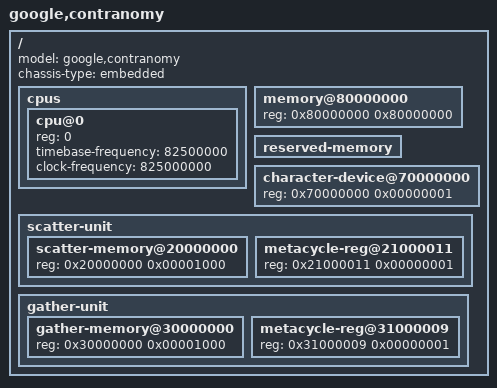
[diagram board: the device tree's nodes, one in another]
// SPDX-FileCopyrightText: 2022 Google LLC
//
// SPDX-License-Identifier: Apache-2.0

/dts-v1/;

/ {

  #address-cells = <1>;
  #size-cells = <1>;

  model = "google,contranomy";

  compatible;

  chassis-type = "embedded";

  cpus {
    #address-cells = <1>;
    #size-cells = <0>;

    cpu@0 {
      device_type = "cpu";
      reg = <0>;

      timebase-frequency = <82500000>; // 8.25 MHz
      clock-frequency = <825000000>; // 825 MHz

      status = "okay";
    };
  };

  memory@80000000 {
    device_type = "memory";
    reg = <0x80000000 0x80000000>;
  };

  reserved-memory {
    #address-cells = <1>;
    #size-cells = <1>;
    ranges;
  };

  character-device@70000000 {
    #address-cells = <1>;
    #size-cells = <1>;
    reg = <0x70000000 0x00000001>;
  };

  scatter-unit {
    #address-cells = <1>;
    #size-cells = <1>;

    scatter-memory@20000000 {
      reg = <0x20000000 0x00001000>;
    };

    metacycle-reg@21000011 {
      reg = <0x21000011 0x00000001>;
    };
  };

  gather-unit {
    #address-cells = <1>;
    #size-cells = <1>;

    gather-memory@30000000 {
      reg = <0x30000000 0x00001000>;
    };

    metacycle-reg@31000009 {
      reg = <0x31000009 0x00000001>;
    };
  };

};
